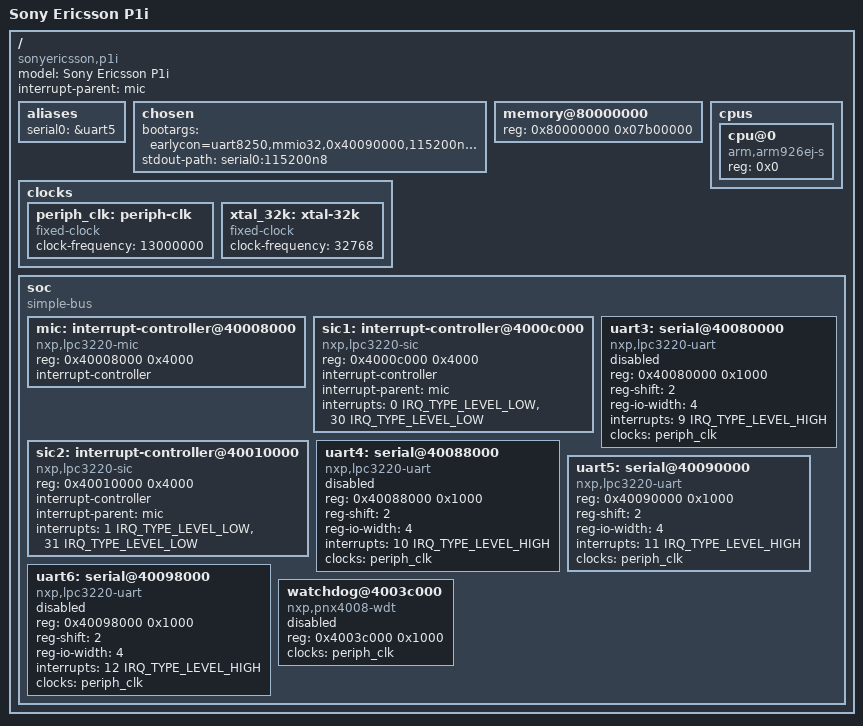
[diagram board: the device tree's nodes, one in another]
// SPDX-License-Identifier: GPL-2.0
/*
 * Sony Ericsson P1i -- NXP (Philips) Nexperia PNX4008, ARM926EJ-S r0p4 @ 208 MHz,
 * 32 KB I + 32 KB D cache, 128 MB SDRAM at 0x80000000.
 *
 * Bring-up DTS: just enough for the decompressor and early boot to talk on UART5
 * (SP2663, 115200 8N1). The handover payload has already set UART5's clock and
 * divisor, so the console works without any clock driver.
 *
 * Built on the LPC32xx layout (the PNX4008's successor, same peripheral map) but NOT on
 * lpc32xx.dtsi: the root compatible deliberately avoids "nxp,lpc32x0", so the generic
 * DT machine is used instead of mach-lpc32xx, whose init code reprograms UART clocks.
 *
 * Verified on the device (uart5probe): UART3-6 bases, MIC/SIC1/SIC2 bases and register
 * layout, clock block at 0x40004000, watchdog at 0x4003c000, UART5 @ 13 MHz / 16 / 7.
 * NOT yet verified: interrupt numbers (taken from LPC32xx), RAM hole position.
 *
 * Build inside a kernel tree, e.g. copy to arch/arm/boot/dts/nxp/lpc/ and run
 *   make ARCH=arm CROSS_COMPILE=arm-linux-gnueabi- nxp/lpc/pnx4008-p1i.dtb
 */

/dts-v1/;

#include <dt-bindings/interrupt-controller/irq.h>

/ {
	model = "Sony Ericsson P1i";
	compatible = "sonyericsson,p1i", "nxp,pnx4008";
	interrupt-parent = <&mic>;
	#address-cells = <1>;
	#size-cells = <1>;

	aliases {
		serial0 = &uart5;	/* -> ttyS0 */
	};

	chosen {
		bootargs = "earlycon=uart8250,mmio32,0x40090000,115200n8 console=ttyS0,115200n8 ignore_loglevel";
		stdout-path = "serial0:115200n8";
	};

	/*
	 * HAL reports 0x7b00000 (123 MB) of 128 MB usable; the missing 5 MB is presumably
	 * framebuffer / modem memory. Assumed at the top (0x87b00000-0x87ffffff) because
	 * Symbian's own page tables live low (TTBR 0x80504000). Confirm against the probe's
	 * RamBootData dump before trusting it; a wrong guess here corrupts memory silently.
	 */
	memory@80000000 {
		device_type = "memory";
		reg = <0x80000000 0x07b00000>;
	};

	cpus {
		#address-cells = <1>;
		#size-cells = <0>;

		cpu@0 {
			compatible = "arm,arm926ej-s";
			device_type = "cpu";
			reg = <0x0>;
		};
	};

	clocks {
		/* PERIPH_CLK: 13 MHz, confirmed by UART5 at divisor 7 -> 116071 baud. */
		periph_clk: periph-clk {
			compatible = "fixed-clock";
			#clock-cells = <0>;
			clock-frequency = <13000000>;
		};

		xtal_32k: xtal-32k {
			compatible = "fixed-clock";
			#clock-cells = <0>;
			clock-frequency = <32768>;
		};
	};

	soc {
		compatible = "simple-bus";
		#address-cells = <1>;
		#size-cells = <1>;
		ranges = <0x40000000 0x40000000 0x10000000>;

		/* Main interrupt controller; register layout ER RSR SR APR ATR ITR (probe). */
		mic: interrupt-controller@40008000 {
			compatible = "nxp,lpc3220-mic";
			reg = <0x40008000 0x4000>;
			interrupt-controller;
			#interrupt-cells = <2>;
		};

		sic1: interrupt-controller@4000c000 {
			compatible = "nxp,lpc3220-sic";
			reg = <0x4000c000 0x4000>;
			interrupt-controller;
			#interrupt-cells = <2>;
			interrupt-parent = <&mic>;
			interrupts = <0 IRQ_TYPE_LEVEL_LOW>, <30 IRQ_TYPE_LEVEL_LOW>;
		};

		sic2: interrupt-controller@40010000 {
			compatible = "nxp,lpc3220-sic";
			reg = <0x40010000 0x4000>;
			interrupt-controller;
			#interrupt-cells = <2>;
			interrupt-parent = <&mic>;
			interrupts = <1 IRQ_TYPE_LEVEL_LOW>, <31 IRQ_TYPE_LEVEL_LOW>;
		};

		/*
		 * Standard 16550-style UARTs, 32-bit registers on a 4-byte stride.
		 * IRQ numbers are LPC32xx's MIC lines -- verify (earlycon is polled and does
		 * not need them; the full ttyS driver does).
		 */
		uart3: serial@40080000 {
			compatible = "nxp,lpc3220-uart", "ns16550a";
			reg = <0x40080000 0x1000>;
			reg-shift = <2>;
			reg-io-width = <4>;
			interrupts = <9 IRQ_TYPE_LEVEL_HIGH>;
			clocks = <&periph_clk>;
			status = "disabled";	/* in use by Symbian's side of the board */
		};

		uart4: serial@40088000 {
			compatible = "nxp,lpc3220-uart", "ns16550a";
			reg = <0x40088000 0x1000>;
			reg-shift = <2>;
			reg-io-width = <4>;
			interrupts = <10 IRQ_TYPE_LEVEL_HIGH>;
			clocks = <&periph_clk>;
			status = "disabled";
		};

		uart5: serial@40090000 {
			compatible = "nxp,lpc3220-uart", "ns16550a";
			reg = <0x40090000 0x1000>;
			reg-shift = <2>;
			reg-io-width = <4>;
			interrupts = <11 IRQ_TYPE_LEVEL_HIGH>;
			clocks = <&periph_clk>;
			status = "okay";
		};

		uart6: serial@40098000 {
			compatible = "nxp,lpc3220-uart", "ns16550a";
			reg = <0x40098000 0x1000>;
			reg-shift = <2>;
			reg-io-width = <4>;
			interrupts = <12 IRQ_TYPE_LEVEL_HIGH>;
			clocks = <&periph_clk>;
			status = "disabled";
		};

		/*
		 * Mainline driver exists (drivers/watchdog/pnx4008_wdt.c). Left disabled: the
		 * handover payload stops it, and enabling it needs a real clock reference.
		 */
		watchdog@4003c000 {
			compatible = "nxp,pnx4008-wdt";
			reg = <0x4003c000 0x1000>;
			clocks = <&periph_clk>;
			status = "disabled";
		};

		/*
		 * TODO system timer. The PNX4008 has no LPC32xx-style timers 0-5, so
		 * "nxp,lpc3220-timer" does not apply. Candidates (the old mach-pnx4008 used HSTIM):
		 *   HSTIM 0x40038000 -- clock gated off under Symbian (TIMCLK_CTRL 0x400040bc bit 1)
		 *   MSTIM 0x40034000 -- running (Symbian's tick)
		 * Needs a small clocksource/clockevent driver. Until then boot stops at
		 * "Calibrating delay loop", which still proves the whole boot chain.
		 */
	};
};
